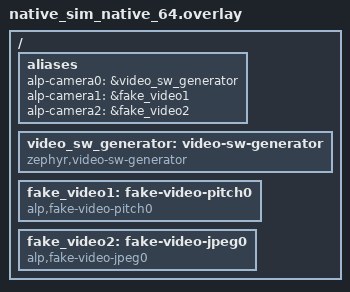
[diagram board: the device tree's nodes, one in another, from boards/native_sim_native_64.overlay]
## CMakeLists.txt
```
# SPDX-License-Identifier: Apache-2.0
cmake_minimum_required(VERSION 3.20.0)
find_package(Zephyr REQUIRED HINTS $ENV{ZEPHYR_BASE})
project(test_camera_video)
target_sources(app PRIVATE
    src/main.c
    src/fake_video_pitch0.c
    src/fake_video_jpeg.c
)
```

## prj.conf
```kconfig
# SPDX-License-Identifier: Apache-2.0
#
# #1628: the decisive offline proof that src/backends/camera/zephyr_video.c
# and src/backends/camera/v2n_n44_isp.c compile against Zephyr v4.4.1's real
# drivers/video/ API.  No other in-repo CONFIG_VIDEO=y configuration enables
# either ALP_SDK_CAMERA_ZEPHYR_VIDEO or ALP_SDK_CAMERA_V2N_N44_ISP -- they
# all disable both, which is exactly why the pre-v4.4 API break went
# uncaught.  This scenario is the one place both are compiled.
#
# CONFIG_ALP_SDK_CAMERA_V2N_N44_ISP is compile-coverage only here: it only
# `depends on VIDEO` (no SoC gating), so it builds fine under native_sim,
# but zephyr_video still wins backend selection at this board's
# silicon_ref="*" -- the ztest below exercises zephyr_video, not this file.

CONFIG_ZTEST=y
CONFIG_ALP_SDK=y
CONFIG_VIDEO=y
CONFIG_ALP_SDK_CAMERA_ZEPHYR_VIDEO=y
CONFIG_ALP_SDK_CAMERA_V2N_N44_ISP=y
CONFIG_LOG=y
```

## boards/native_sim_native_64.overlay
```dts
/*
 * Copyright 2026 Alp Lab AB
 * SPDX-License-Identifier: Apache-2.0
 *
 * Devicetree overlay for the alp-sdk camera_video ztest under native_sim
 * (#1628).  Wires three emulated video devices to the alias names
 * src/backends/camera/zephyr_video.c looks up:
 *   - alp-camera0 -> zephyr,video-sw-generator (upstream driver, fills
 *     video_format.pitch on set_format): the general open/start/capture/
 *     release/stop/close round trip.
 *   - alp-camera1 -> alp,fake-video-pitch0 (this test's own fixture,
 *     leaves pitch == 0): the Part 2 buffer-sizing regression check.
 *   - alp-camera2 -> alp,fake-video-jpeg0 (this test's own fixture,
 *     defaults to VIDEO_PIX_FMT_JPEG with pitch == 0): the review
 *     follow-up compressed-format sizing check.
 */

/ {
	aliases {
		alp-camera0 = &video_sw_generator;
		alp-camera1 = &fake_video1;
		alp-camera2 = &fake_video2;
	};

	video_sw_generator: video-sw-generator {
		compatible = "zephyr,video-sw-generator";
		status = "okay";
	};

	fake_video1: fake-video-pitch0 {
		compatible = "alp,fake-video-pitch0";
		status = "okay";
	};

	fake_video2: fake-video-jpeg0 {
		compatible = "alp,fake-video-jpeg0";
		status = "okay";
	};
};
```

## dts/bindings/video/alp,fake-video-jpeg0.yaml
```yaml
# Copyright 2026 Alp Lab AB
# SPDX-License-Identifier: Apache-2.0
#
# Fake video device for the alp-sdk camera_video ztest (#1628 review
# follow-up).  Lives only in this test.

description: |
  Boots with VIDEO_PIX_FMT_JPEG already set as its current format and
  pitch left at 0 -- video_bits_per_pixel() has no JPEG entry and returns
  0, the exact arrangement a real MJPEG sensor (e.g. drivers/video/
  ov2640.c) exposes.  Advertises no format_caps entries a portable
  ALP_PIXFMT_* enum value maps to, so alp_camera_open() with the enum's
  zero value (ALP_PIXFMT_MONO_VLSB) takes the readback branch and must
  fall back to the flat w*h*2 heuristic bound instead of hard-refusing
  with ALP_ERR_NOSUPPORT.

compatible: "alp,fake-video-jpeg0"
```

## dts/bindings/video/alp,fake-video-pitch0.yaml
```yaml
# Copyright 2026 Alp Lab AB
# SPDX-License-Identifier: Apache-2.0
#
# Fake video device for the alp-sdk camera_video ztest (#1628).  Lives only
# in this test.

description: |
  Advertises VIDEO_PIX_FMT_RGB24 (24 bpp -- a format Zephyr's
  video_bits_per_pixel table can size) but, like some real sensor/bridge
  drivers, never fills video_format.pitch in its set_format hook.  That is
  the exact arrangement issue #1628 Part 2 depends on: the zephyr_video /
  v2n_n44_isp backends must derive bytes-per-pixel from the negotiated
  fourcc when pitch stays 0, not assume a flat 2 B/px.  Its enqueue hook
  refuses any video_buffer smaller than width * height * 3, standing in for
  the CSI-2/ISP DMA overrun an under-sized buffer would suffer on real
  silicon.

compatible: "alp,fake-video-pitch0"
```

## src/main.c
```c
/*
 * Copyright 2026 Alp Lab AB
 * SPDX-License-Identifier: Apache-2.0
 *
 * #1628: proves src/backends/camera/zephyr_video.c both compiles and
 * behaves correctly against the pinned Zephyr v4.4.1 drivers/video/ API.
 *
 * Part 1 (compile + basic operation): no other in-repo CONFIG_VIDEO=y
 * scenario also sets CONFIG_ALP_SDK_CAMERA_ZEPHYR_VIDEO=y, so this is the
 * only build that actually compiles the file -- see prj.conf.  camera0
 * (backed by the upstream zephyr,video-sw-generator, which fills
 * video_format.pitch on set_format) round-trips open/start/capture/
 * release/stop/close through the ported v4.4 API.
 *
 * Part 2 (buffer sizing): camera1 (backed by this test's own
 * alp,fake-video-pitch0 fixture, which never fills pitch) proves open()
 * derives bytes-per-pixel from the negotiated fourcc instead of assuming
 * a flat 2 B/px -- the fixture's enqueue hook refuses any video_buffer
 * smaller than width * height * 3 bytes for RGB888, reproducing the
 * CSI-2/ISP DMA overrun the old flat-2-B/px sizing would have caused.
 *
 * Part 3 (JPEG / compressed-format sizing, review follow-up): camera2
 * (backed by this test's own alp,fake-video-jpeg0 fixture, which reports
 * VIDEO_PIX_FMT_JPEG with pitch == 0) proves open() falls back to the
 * flat w*h*2 heuristic bound for a fourcc video_bits_per_pixel() can't
 * size at all, instead of hard-refusing with ALP_ERR_NOSUPPORT.
 */

#include <zephyr/ztest.h>

#include <alp/camera.h>

ZTEST(camera_video, test_zephyr_video_open_start_capture_close_roundtrip)
{
	alp_camera_config_t cfg = ALP_CAMERA_CONFIG_DEFAULT(0);

	cfg.width  = 320;
	cfg.height = 160;
	cfg.format = ALP_PIXFMT_RGB565;

	alp_camera_t *cam = alp_camera_open(&cfg);

	zassert_not_null(cam, "camera0 open failed: %d", alp_last_error());

	zassert_equal(alp_camera_start(cam), ALP_OK);

	alp_camera_frame_t frame  = { 0 };
	alp_status_t       status = alp_camera_capture(cam, &frame, 1000);

	zassert_equal(status, ALP_OK, "capture failed: %d", status);
	zassert_not_null(frame.data);
	zassert_true(frame.size > 0, "captured frame reported zero size");

	zassert_equal(alp_camera_release(cam, &frame), ALP_OK);
	zassert_equal(alp_camera_stop(cam), ALP_OK);
	alp_camera_close(cam);
}

ZTEST(camera_video, test_zephyr_video_pitch_zero_sizes_by_fourcc_not_flat_2bpp)
{
	alp_camera_config_t cfg = ALP_CAMERA_CONFIG_DEFAULT(1);

	cfg.width  = 64;
	cfg.height = 48;
	cfg.format = ALP_PIXFMT_RGB888;

	alp_camera_t *cam = alp_camera_open(&cfg);

	zassert_not_null(
	    cam, "camera1 open failed -- buffer under-sized for RGB888? err=%d", alp_last_error());

	alp_camera_close(cam);
}

ZTEST(camera_video, test_zephyr_video_jpeg_pitch_zero_falls_back_to_flat_heuristic)
{
	alp_camera_config_t cfg = ALP_CAMERA_CONFIG_DEFAULT(2);

	/* ALP_PIXFMT_MONO_VLSB is the enum's zero value: _to_video_fourcc()
	 * maps it to 0, so open() takes the readback branch and negotiates
	 * nothing -- it just reads back camera2's already-JPEG default via
	 * video_get_format(). */
	cfg.format = ALP_PIXFMT_MONO_VLSB;

	alp_camera_t *cam = alp_camera_open(&cfg);

	zassert_not_null(cam, "camera2 (JPEG default, pitch==0) open failed: %d", alp_last_error());

	alp_camera_close(cam);
}

ZTEST_SUITE(camera_video, NULL, NULL, NULL, NULL, NULL);
```

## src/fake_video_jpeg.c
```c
/*
 * Copyright 2026 Alp Lab AB
 * SPDX-License-Identifier: Apache-2.0
 *
 * Fake drivers/video/ device for the alp-sdk camera_video ztest (#1628
 * review follow-up).  Boots already set to VIDEO_PIX_FMT_JPEG with pitch
 * left at 0 -- video_bits_per_pixel() has no table entry for JPEG and
 * returns 0, and this is the exact shape a real MJPEG sensor (e.g.
 * drivers/video/ov2640.c, which advertises VIDEO_PIX_FMT_JPEG at ten
 * resolutions and never writes fmt->pitch) exposes before any
 * alp_camera_open() negotiation.
 *
 * get_caps() advertises no format_caps entries whose pixelformat the
 * portable ALP_PIXFMT_* enum can request, so a caller that asks for the
 * enum's zero value (ALP_PIXFMT_MONO_VLSB, which _to_video_fourcc() maps
 * to 0) takes the else/readback branch in zephyr_video.c / v2n_n44_isp.c:
 * video_get_format() reads back this driver's already-JPEG default
 * instead of negotiating a new one.  That is the path the #1628 review
 * found hard-refusing with ALP_ERR_NOSUPPORT instead of falling back to
 * the flat w*h*2 heuristic bound compressed formats need.
 */

#define DT_DRV_COMPAT alp_fake_video_jpeg0

#include <errno.h>

#include <zephyr/drivers/video.h>
#include <zephyr/kernel.h>

#define FAKE_JPEG_WIDTH  320
#define FAKE_JPEG_HEIGHT 240

struct fake_video_jpeg_data {
	struct video_format fmt;
};

static int _get_caps(const struct device *dev, struct video_caps *caps)
{
	ARG_UNUSED(dev);
	caps->format_caps    = NULL;
	caps->min_vbuf_count = 1;
	return 0;
}

static int _get_fmt(const struct device *dev, struct video_format *fmt)
{
	struct fake_video_jpeg_data *data = dev->data;

	*fmt = data->fmt;
	return 0;
}

static int _set_stream(const struct device *dev, bool enable, enum video_buf_type type)
{
	ARG_UNUSED(dev);
	ARG_UNUSED(enable);
	ARG_UNUSED(type);
	return 0;
}

static int _enqueue(const struct device *dev, struct video_buffer *buf)
{
	struct fake_video_jpeg_data *data = dev->data;
	/* Stand-in for the flat w*h*2 heuristic bound the backend must fall
	 * back to for JPEG -- refuses anything smaller, standing in for the
	 * DMA overrun an under-sized buffer would suffer on real silicon. */
	uint32_t need = (uint32_t)data->fmt.width * data->fmt.height * 2u;

	if (buf->size < need) {
		return -ENOBUFS;
	}
	return 0;
}

static const struct video_driver_api _api = {
	.get_format = _get_fmt,
	.set_stream = _set_stream,
	.get_caps   = _get_caps,
	.enqueue    = _enqueue,
};

static struct fake_video_jpeg_data _data0 = {
	.fmt =
	    {
	        .pixelformat = VIDEO_PIX_FMT_JPEG,
	        .width       = FAKE_JPEG_WIDTH,
	        .height      = FAKE_JPEG_HEIGHT,
	        .pitch       = 0,
	    },
};

DEVICE_DT_INST_DEFINE(0, NULL, NULL, &_data0, NULL, POST_KERNEL, CONFIG_VIDEO_INIT_PRIORITY, &_api);
```

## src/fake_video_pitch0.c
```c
/*
 * Copyright 2026 Alp Lab AB
 * SPDX-License-Identifier: Apache-2.0
 *
 * Fake drivers/video/ device for the alp-sdk camera_video ztest (#1628,
 * Part 2).  Advertises VIDEO_PIX_FMT_RGB24 (24 bpp -- sizeable via
 * Zephyr's video_bits_per_pixel table) but deliberately never fills
 * video_format.pitch in set_format, the exact arrangement in which a
 * driver-reported pitch cannot be trusted and the caller must derive
 * bytes-per-pixel from the negotiated fourcc instead.  enqueue() refuses
 * any video_buffer smaller than width * height * 3 bytes, standing in for
 * the CSI-2/ISP DMA overrun an under-sized buffer would suffer on real
 * silicon.
 */

#define DT_DRV_COMPAT alp_fake_video_pitch0

#include <errno.h>

#include <zephyr/drivers/video.h>
#include <zephyr/kernel.h>

static const struct video_format_cap _fmts[] = {
	{
	    .pixelformat = VIDEO_PIX_FMT_RGB24,
	    .width_min   = 8,
	    .width_max   = 640,
	    .height_min  = 8,
	    .height_max  = 480,
	    .width_step  = 1,
	    .height_step = 1,
	},
	{ 0 },
};

struct fake_video_pitch0_data {
	struct video_format fmt;
};

static int _get_caps(const struct device *dev, struct video_caps *caps)
{
	ARG_UNUSED(dev);
	caps->format_caps    = _fmts;
	caps->min_vbuf_count = 1;
	return 0;
}

static int _set_fmt(const struct device *dev, struct video_format *fmt)
{
	struct fake_video_pitch0_data *data = dev->data;

	if (fmt->pixelformat != VIDEO_PIX_FMT_RGB24) {
		return -ENOTSUP;
	}
	/* Deliberately leave fmt->pitch untouched (0) -- the arrangement
	 * under test. */
	data->fmt = *fmt;
	return 0;
}

static int _get_fmt(const struct device *dev, struct video_format *fmt)
{
	struct fake_video_pitch0_data *data = dev->data;

	*fmt = data->fmt;
	return 0;
}

static int _set_stream(const struct device *dev, bool enable, enum video_buf_type type)
{
	ARG_UNUSED(dev);
	ARG_UNUSED(enable);
	ARG_UNUSED(type);
	return 0;
}

static int _enqueue(const struct device *dev, struct video_buffer *buf)
{
	struct fake_video_pitch0_data *data = dev->data;
	uint32_t                       need = (uint32_t)data->fmt.width * data->fmt.height * 3u;

	if (buf->size < need) {
		return -ENOBUFS;
	}
	return 0;
}

static const struct video_driver_api _api = {
	.set_format = _set_fmt,
	.get_format = _get_fmt,
	.set_stream = _set_stream,
	.get_caps   = _get_caps,
	.enqueue    = _enqueue,
};

static struct fake_video_pitch0_data _data0;

DEVICE_DT_INST_DEFINE(0, NULL, NULL, &_data0, NULL, POST_KERNEL, CONFIG_VIDEO_INIT_PRIORITY, &_api);
```
